# MDR32FG16S1QI register map
Vendor: Milandr; File version: 1.0
CPU: CM3 r1p1, little endian, MPU, no FPU, 3 interrupt priority bits
Registers are 32-bit, read-write, reset 0x0 unless marked. A register's access mark holds for its fields unless they carry their own. Offsets are from the block's base; [hi:lo] are bit positions; {n}, {i} and the like mark numbered series; 'fields as' and 'values as' point back to an identical list.

## MDR_POWER — POWER
Base 0x40058000
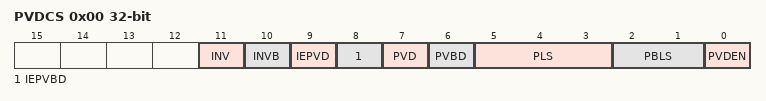
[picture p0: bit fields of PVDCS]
0x00 PVDCS — POWER Power Detector Control/Status Register
  [11] INV, [10] INVB, [9] IEPVD, [8] IEPVBD, [7] PVD, [6] PVBD, [5:3] PLS, [2:1] PBLS, [0] PVDEN

## MDR_WWDG — WWDT
Base 0x40060000
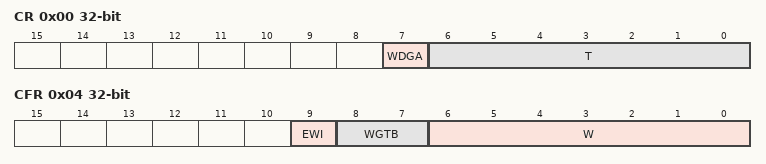
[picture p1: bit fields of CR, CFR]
0x00 CR — WWDG Command Register
  [7] WDGA, [6:0] T
0x04 CFR — WWDG Configuration Register
  [9] EWI, [8:7] WGTB, [6:0] W
0x08 SR — WWDG Status Register
  [0] EWIF

## MDR_IWDG — IWDT
Base 0x40068000
0x00 KR — IWDG Key Register
  [15:0] KEY
0x04 PR — IWDG Clock Prescaler Register
  [2:0] PR
0x08 RLR — IWDG Reload Register
  [11:0] RLR
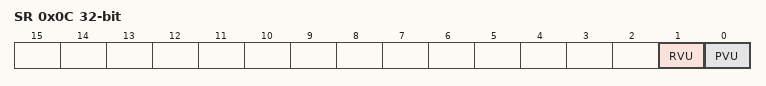
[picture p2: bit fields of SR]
0x0C SR — IWDG Status Register
  [1] RVU, [0] PVU

## MDR_TIMER1 — TIMER1
Base 0x40070000
Same registers: MDR_TIMER2 0x40078000, MDR_TIMER3 0x40080000
0x00 CNT — Timer Counter Register
  [15:0] CNT
0x04 PSG — Timer Clock Prescaler Register
  [15:0] PSG
0x08 ARR — Timer Auto-Reload Register
  [15:0] ARR
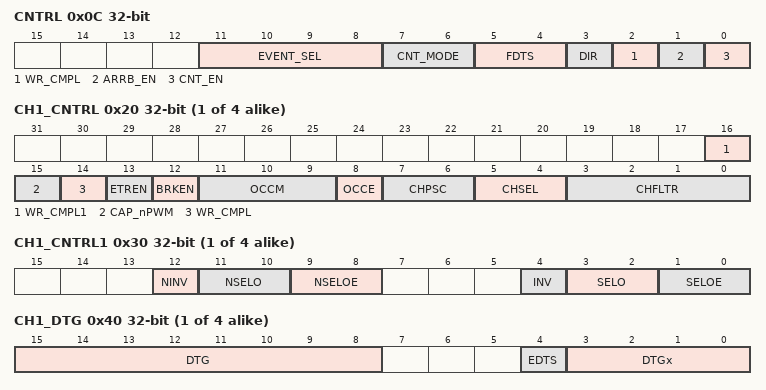
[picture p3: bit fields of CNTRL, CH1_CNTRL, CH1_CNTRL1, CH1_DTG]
0x0C CNTRL — Timer Control Register
  [11:8] EVENT_SEL, [7:6] CNT_MODE, [5:4] FDTS, [3] DIR, [2] WR_CMPL, [1] ARRB_EN, [0] CNT_EN
{0xC+4i} CCR{i} (i=1..4) — Timer Capture/Compare Register
  [15:0] CCR
{0x1C+4i} CH{i}_CNTRL (reset mask 0xFFFF) (i=1..4) — Timer Channel Control Register
  [16] WR_CMPL1 ro, [15] CAP_nPWM, [14] WR_CMPL ro, [13] ETREN, [12] BRKEN, [11:9] OCCM, [8] OCCE, [7:6] CHPSC, [5:4] CHSEL, [3:0] CHFLTR
{0x2C+4i} CH{i}_CNTRL1 (i=1..4) — Timer Channel Control1 Register
  [12] NINV, [11:10] NSELO, [9:8] NSELOE, [4] INV, [3:2] SELO, [1:0] SELOE
{0x3C+4i} CH{i}_DTG (i=1..4) — Timer Channel DTG Register
  [15:8] DTG, [4] EDTS, [3:0] DTGx
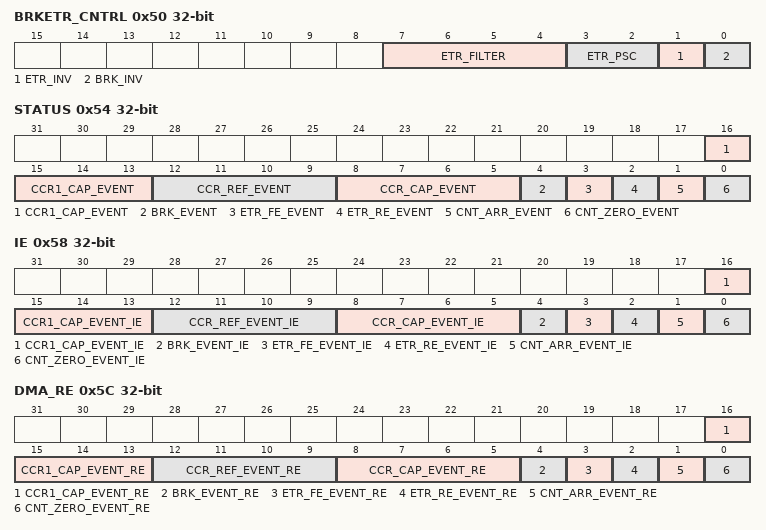
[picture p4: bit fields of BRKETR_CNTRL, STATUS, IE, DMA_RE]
0x50 BRKETR_CNTRL — Timer BRK/ETR Control Register
  [7:4] ETR_FILTER, [3:2] ETR_PSC, [1] ETR_INV, [0] BRK_INV
0x54 STATUS — Timer Status Register
  [16:13] CCR1_CAP_EVENT, [12:9] CCR_REF_EVENT, [8:5] CCR_CAP_EVENT, [4] BRK_EVENT, [3] ETR_FE_EVENT, [2] ETR_RE_EVENT, [1] CNT_ARR_EVENT, [0] CNT_ZERO_EVENT
0x58 IE — Timer Interrupt Enable Register
  [16:13] CCR1_CAP_EVENT_IE, [12:9] CCR_REF_EVENT_IE, [8:5] CCR_CAP_EVENT_IE, [4] BRK_EVENT_IE, [3] ETR_FE_EVENT_IE, [2] ETR_RE_EVENT_IE, [1] CNT_ARR_EVENT_IE, [0] CNT_ZERO_EVENT_IE
0x5C DMA_RE — Timer DMA Request Enable Register
  [16:13] CCR1_CAP_EVENT_RE, [12:9] CCR_REF_EVENT_RE, [8:5] CCR_CAP_EVENT_RE, [4] BRK_EVENT_RE, [3] ETR_FE_EVENT_RE, [2] ETR_RE_EVENT_RE, [1] CNT_ARR_EVENT_RE, [0] CNT_ZERO_EVENT_RE
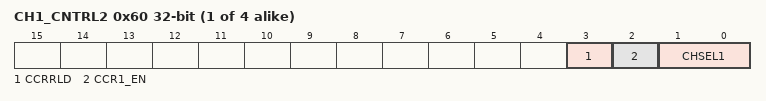
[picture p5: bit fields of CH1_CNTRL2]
{0x5C+4i} CH{i}_CNTRL2 (i=1..4) — Timer Channel Control2 Register
  [3] CCRRLD, [2] CCR1_EN, [1:0] CHSEL1
0x70 CCR11 — Timer Capture/Compare1 Register
  [15:0] CCR
0x74 CCR21 — Timer Capture/Compare1 Register
  [15:0] CCR
0x78 CCR31 — Timer Capture/Compare1 Register
  [15:0] CCR
0x7C CCR41 — Timer Capture/Compare1 Register
  [15:0] CCR

## MDR_ADC — ADC
Base 0x40088000
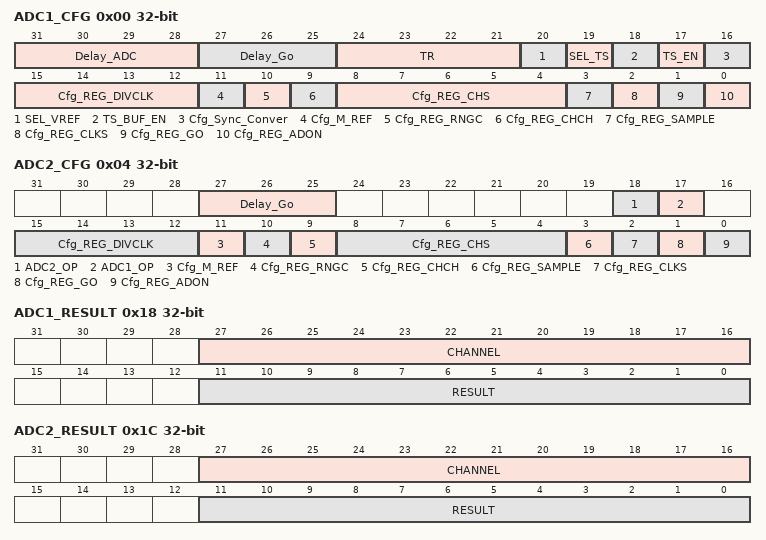
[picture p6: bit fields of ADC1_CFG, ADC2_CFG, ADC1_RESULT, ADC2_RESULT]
0x00 ADC1_CFG — ADC1 Configuration Register
  [31:28] Delay_ADC, [27:25] Delay_Go, [24:21] TR, [20] SEL_VREF, [19] SEL_TS, [18] TS_BUF_EN, [17] TS_EN, [16] Cfg_Sync_Conver, [15:12] Cfg_REG_DIVCLK, [11] Cfg_M_REF, [10] Cfg_REG_RNGC, [9] Cfg_REG_CHCH, [8:4] Cfg_REG_CHS, [3] Cfg_REG_SAMPLE, [2] Cfg_REG_CLKS, [1] Cfg_REG_GO, [0] Cfg_REG_ADON
0x04 ADC2_CFG — ADC2 Configuration Register
  [27:25] Delay_Go, [18] ADC2_OP, [17] ADC1_OP, [15:12] Cfg_REG_DIVCLK, [11] Cfg_M_REF, [10] Cfg_REG_RNGC, [9] Cfg_REG_CHCH, [8:4] Cfg_REG_CHS, [3] Cfg_REG_SAMPLE, [2] Cfg_REG_CLKS, [1] Cfg_REG_GO, [0] Cfg_REG_ADON
0x08 ADC1_H_LEVEL — ADC1 High Level Register
  [11:0] REG_H_LEVEL
0x0C ADC2_H_LEVEL — ADC2 High Level Register
  [11:0] REG_H_LEVEL
0x10 ADC1_L_LEVEL — ADC1 Low Level Register
  [11:0] REG_L_LEVEL
0x14 ADC2_L_LEVEL — ADC2 Low Level Register
  [11:0] REG_L_LEVEL
0x18 ADC1_RESULT
  [27:16] CHANNEL, [11:0] RESULT
0x1C ADC2_RESULT
  [27:16] CHANNEL, [11:0] RESULT
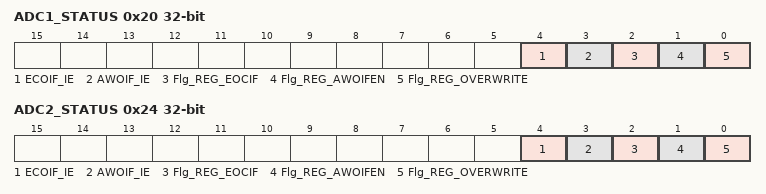
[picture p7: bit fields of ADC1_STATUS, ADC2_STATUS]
0x20 ADC1_STATUS
  [4] ECOIF_IE, [3] AWOIF_IE, [2] Flg_REG_EOCIF, [1] Flg_REG_AWOIFEN, [0] Flg_REG_OVERWRITE
0x24 ADC2_STATUS
  fields as ADC1_STATUS
0x28 ADC1_CHSEL — ADC1 Channel Selector Register
  [31:0] Sl_Ch_Ch_REF
0x2C ADC2_CHSEL — ADC2 Channel Selector Register
  [31:0] Sl_Ch_Ch_REF
